# Q32M210 register map
File version: 1.0
Registers are 32-bit, read-write, no defined reset value unless marked. A register's access mark holds for its fields unless they carry their own. Offsets are from the block's base; [hi:lo] are bit positions; {n}, {i} and the like mark numbered series.

## USB_Interface
Base 0x40000B00
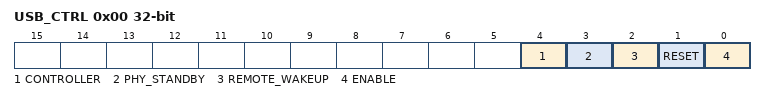
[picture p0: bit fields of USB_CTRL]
0x00 USB_CTRL — USB Control
  [4] CONTROLLER — Select whether data transfer will be controlled by the ARM Cortex-M3 processor or the DMA
    0=USB_CONTROLLER_CM3 (The ARM Cortex-M3 controls data transfers using USB); 1=USB_CONTROLLER_DMA (The DMA controls data transfers using USB)
  [3] PHY_STANDBY — Put the USB PHY into standby mode
    0=USB_PHY_ENABLED (The USB PHY is enabled); 1=USB_PHY_STANDBY (The USB PHY is in standby mode)
  [2] REMOTE_WAKEUP — Initiate a remote wakeup sequence
    1=USB_REMOTE_WAKEUP (Trigger a USB remote wakeup sequence)
  [1] RESET — Reset the USB interface controller
    1=USB_RESET_ENABLE (Trigger a USB controller reset (requires the controller to be enabled)); 0=USB_RESET_DISABLE (Disables a USB controller reset)
  [0] ENABLE — Enable/disable the USB interface controller
    0=USB_DISABLE (Disable the USB controller); 1=USB_ENABLE (Enable the USB controller)

## Timer_0_to_3_Configuration_and_Control
Base 0x40000C00
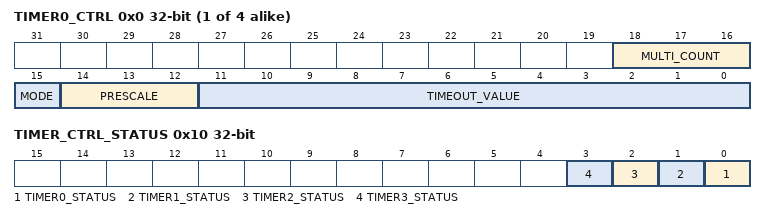
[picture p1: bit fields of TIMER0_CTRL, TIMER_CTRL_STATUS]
{0x0+4i} TIMER{i}_CTRL (i=0..3) — Timer {i} Control and Configuration
  [18:16] MULTI_COUNT — Specify the number of timeouts for a terminating timer sequence on timer {i}
    0=TIMER{i}_COUNT_1 (Stop timer {i} after 1 timeout); {v}=TIMER{i}_COUNT_{v+1} (Stop timer {i} after {v+1} timeouts) (v=1..7)
  [15] MODE — Select timer operation mode
    0=TIMER{i}_FIXED_COUNT_RUN (Run timer {i} until a fixed number of timeouts has occurred); 1=TIMER{i}_FREE_RUN (Run timer {i} continuously)
  [14:12] PRESCALE — Prescaler for timer {i}
    0=TIMER{i}_PRESCALE_1 (Prescale timer {i} by 1); 1=TIMER{i}_PRESCALE_2 (Prescale timer {i} by 2); 2=TIMER{i}_PRESCALE_4 (Prescale timer {i} by 4); 3=TIMER{i}_PRESCALE_8 (Prescale timer {i} by 8); 4=TIMER{i}_PRESCALE_16 (Prescale timer {i} by 16); 5=TIMER{i}_PRESCALE_32 (Prescale timer {i} by 32); 6=TIMER{i}_PRESCALE_64 (Prescale timer {i} by 64); 7=TIMER{i}_PRESCALE_128 (Prescale timer {i} by 128)
  [11:0] TIMEOUT_VALUE — Number of prescaled timer pulses before the timer {i} timeout occurs
0x10 TIMER_CTRL_STATUS — Timer Control Status for Timer 0 and Timer 1
  [n] TIMER{n}_STATUS (n=0..3) — Used to start timer {n} and indicate the timer status
    0=TIMER{n}_STOP (Stop timer {n} (also indicate that timer is not running)); 1=TIMER{n}_START (Start timer {n} (also indicate that timer is running))

## Watchdog_Timer_Configuration_and_Control
Base 0x40000D00
0x00 WATCHDOG_REFRESH_CTRL — Watchdog Refresh Control
  [0] REFRESH — Used to restart the Watchdog timer to prevent a watchdog reset. An application should periodically write to this bit.
    1=WATCHDOG_REFRESH (Restart the watchdog timer.)
0x04 WATCHDOG_CTRL — Watchdog Timer Control
  [3:0] TIMEOUT — Select a timeout frequency between 2048 and 4194304 cycles, which is 2.048 ms and 4.194 s (based on a 1 MHz system clock)
    0=WATCHDOG_TIMEOUT_2E11 (A watchdog timeout will occur after 2048 (2^11) cycles); 1=WATCHDOG_TIMEOUT_2E12 (A watchdog timeout will occur after 4096 (2^12) cycles); 2=WATCHDOG_TIMEOUT_2E13 (A watchdog timeout will occur after 8192 (2^13) cycles); 3=WATCHDOG_TIMEOUT_2E14 (A watchdog timeout will occur after 16384 (2^14) cycles); 4=WATCHDOG_TIMEOUT_2E15 (A watchdog timeout will occur after 32768 (2^15) cycles); 5=WATCHDOG_TIMEOUT_2E16 (A watchdog timeout will occur after 65536 (2^16) cycles); 6=WATCHDOG_TIMEOUT_2E17 (A watchdog timeout will occur after 131072 (2^17) cycles); 7=WATCHDOG_TIMEOUT_2E18 (A watchdog timeout will occur after 262144 (2^18) cycles); 8=WATCHDOG_TIMEOUT_2E19 (A watchdog timeout will occur after 524288 (2^19) cycles); 9=WATCHDOG_TIMEOUT_2E20 (A watchdog timeout will occur after 1048576 (2^20) cycles); 10=WATCHDOG_TIMEOUT_2E21 (A watchdog timeout will occur after 2097152 (2^21) cycles); 11=WATCHDOG_TIMEOUT_2E22 (A watchdog timeout will occur after 4194304 (2^22) cycles)
